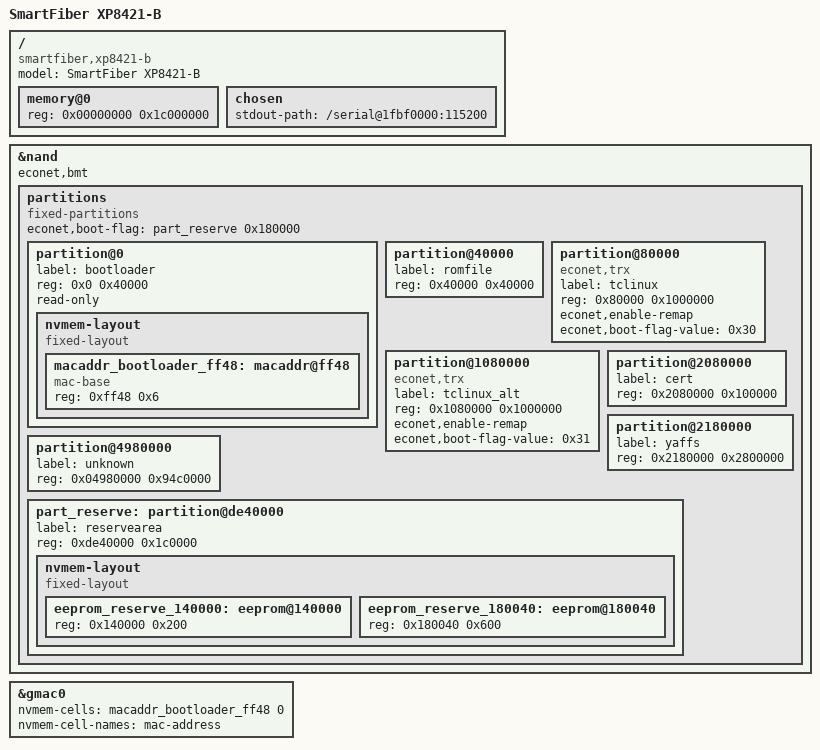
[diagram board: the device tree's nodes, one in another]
// SPDX-License-Identifier: (GPL-2.0-only OR BSD-2-Clause)
/dts-v1/;

#include "en751221.dtsi"

/ {
	model = "SmartFiber XP8421-B";
	compatible = "smartfiber,xp8421-b", "econet,en751221";

	memory@0 {
		device_type = "memory";
		reg = <0x00000000 0x1c000000>;
	};

	chosen {
		stdout-path = "/serial@1fbf0000:115200";
	};
};

&nand {
	status = "okay";
	econet,bmt;

	partitions {
		compatible = "fixed-partitions";
		#address-cells = <1>;
		#size-cells = <1>;

		econet,boot-flag = <&part_reserve 0x180000>;

		partition@0 {
			label = "bootloader";
			reg = <0x0 0x40000>;
			read-only;

			nvmem-layout {
				compatible = "fixed-layout";
				#address-cells = <1>;
				#size-cells = <1>;

				macaddr_bootloader_ff48: macaddr@ff48 {
					compatible = "mac-base";
					reg = <0xff48 0x6>;
					#nvmem-cell-cells = <1>;
				};
			};
		};

		partition@40000 {
			label = "romfile";
			reg = <0x40000 0x40000>;
		};

		partition@80000 {
			compatible = "econet,trx";
			label = "tclinux";
			reg = <0x80000 0x1000000>;
			econet,enable-remap;
			econet,boot-flag-value = <0x30>;
		};

		partition@1080000 {
			compatible = "econet,trx";
			label = "tclinux_alt";
			reg = <0x1080000 0x1000000>;
			econet,enable-remap;
			econet,boot-flag-value = <0x31>;
		};

		partition@2080000 {
			label = "cert";
			reg = <0x2080000 0x100000>;
		};

		partition@2180000 {
			label = "yaffs";
			reg = <0x2180000 0x2800000>;
		};

		partition@4980000 {
			label = "unknown";
			reg = <0x04980000 0x94c0000>;
		};

		part_reserve: partition@de40000 {
			label = "reservearea";
			reg = <0xde40000 0x1c0000>;

			nvmem-layout {
				compatible = "fixed-layout";
				#address-cells = <1>;
				#size-cells = <1>;

				eeprom_reserve_140000: eeprom@140000 {
					/* MT7592 */
					reg = <0x140000 0x200>;
				};

				eeprom_reserve_180040: eeprom@180040 {
					/* MT7612E */
					reg = <0x180040 0x600>;
				};
			};
		};
	};
};

&gmac0 {
	status = "okay";
	nvmem-cells = <&macaddr_bootloader_ff48 0>;
	nvmem-cell-names = "mac-address";
};
